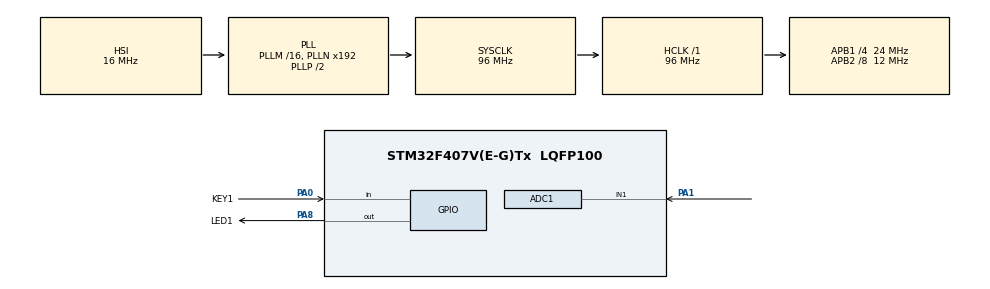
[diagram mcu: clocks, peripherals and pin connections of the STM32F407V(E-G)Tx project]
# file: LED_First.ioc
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ADC1.Channel-1\#ChannelRegularConversion=ADC_CHANNEL_1
ADC1.ContinuousConvMode=ENABLE
ADC1.NbrOfConversionFlag=1
ADC1.Rank-1\#ChannelRegularConversion=1
ADC1.SamplingTime-1\#ChannelRegularConversion=ADC_SAMPLETIME_3CYCLES
ADC1.master=1
FREERTOS.Tasks01=LED_Task,24,128,LED_Entry,As weak,NULL,Static,LED_TaskBuffer,LED_TaskControlBlock
Mcu.Family=STM32F4
Mcu.Name=STM32F407V(E-G)Tx
Mcu.Package=LQFP100
NVIC.PriorityGroup=NVIC_PRIORITYGROUP_4
NVIC.TIM6_DAC_IRQn=true\:15\:0\:false\:false\:true\:false\:false\:true\:true
NVIC.TimeBase=TIM6_DAC_IRQn
NVIC.TimeBaseIP=TIM6
PA0-WKUP.GPIO_Label=KEY1
PA0-WKUP.GPIO_Mode=GPIO_MODE_INPUT
PA0-WKUP.GPIO_PuPd=GPIO_PULLUP
PA0-WKUP.Signal=GPIO_Input
PA1.Signal=ADCx_IN1
PA13.Mode=Serial_Wire
PA13.Signal=SYS_JTMS-SWDIO
PA14.Mode=Serial_Wire
PA14.Signal=SYS_JTCK-SWCLK
PA8.GPIO_Label=LED1
PA8.GPIO_PuPd=GPIO_PULLUP
PA8.Signal=GPIO_Output
PH0-OSC_IN.Mode=HSE-External-Oscillator
PH0-OSC_IN.Signal=RCC_OSC_IN
PH1-OSC_OUT.Mode=HSE-External-Oscillator
PH1-OSC_OUT.Signal=RCC_OSC_OUT
ProjectManager.HeapSize=0x200
ProjectManager.StackSize=0x400
ProjectManager.TargetToolchain=MDK-ARM V5.32
RCC.AHBFreq_Value=96000000
RCC.APB1CLKDivider=RCC_HCLK_DIV4
RCC.APB1Freq_Value=24000000
RCC.APB1TimFreq_Value=48000000
RCC.APB2CLKDivider=RCC_HCLK_DIV8
RCC.APB2Freq_Value=12000000
RCC.APB2TimFreq_Value=24000000
RCC.CortexFreq_Value=96000000
RCC.HCLKFreq_Value=96000000
RCC.HSE_VALUE=25000000
RCC.HSI_VALUE=16000000
RCC.LSE_VALUE=32768
RCC.SYSCLKFreq_VALUE=96000000
RCC.SYSCLKSource=RCC_SYSCLKSOURCE_PLLCLK
RCC.VCOOutputFreq_Value=192000000
SH.ADCx_IN1.0=ADC1_IN1,IN1
VP_FREERTOS_VS_CMSIS_V2.Mode=CMSIS_V2
VP_SYS_VS_tim6.Mode=TIM6
board=custom

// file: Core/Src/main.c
/* USER CODE BEGIN Header */
/**
  ******************************************************************************
  * @file           : main.c
  * @brief          : Main program body
  ******************************************************************************
  * @attention
  *
  * Copyright (c) 2023 STMicroelectronics.
  * All rights reserved.
  *
  * This software is licensed under terms that can be found in the LICENSE file
  * in the root directory of this software component.
  * If no LICENSE file comes with this software, it is provided AS-IS.
  *
  ******************************************************************************
  */
/* USER CODE END Header */
#include "main.h"
#include "cmsis_os.h"
#include "adc.h"
#include "gpio.h"

/* USER CODE BEGIN Includes */
// #include "SEGGER_RRT.h"

/* USER CODE END Includes */

void SystemClock_Config(void);
void MX_FREERTOS_Init(void);

int main(void)
{

  /* MCU Configuration--------------------------------------------------------*/

  /* Reset of all peripherals, Initializes the Flash interface and the Systick. */
  HAL_Init();

  /* Configure the system clock */
  SystemClock_Config();

  /* Initialize all configured peripherals */
  MX_GPIO_Init();
  MX_ADC1_Init();

  /* Init scheduler */
  osKernelInitialize();  /* Call init function for freertos objects (in freertos.c) */
  MX_FREERTOS_Init();

  /* Start scheduler */
  osKernelStart();

  /* We should never get here as control is now taken by the scheduler */
  /* Infinite loop */
  while (1)
  {

  }
}

void SystemClock_Config(void)
{
  RCC_OscInitTypeDef RCC_OscInitStruct = {0};
  RCC_ClkInitTypeDef RCC_ClkInitStruct = {0};

  /** Configure the main internal regulator output voltage
  */
  __HAL_RCC_PWR_CLK_ENABLE();
  __HAL_PWR_VOLTAGESCALING_CONFIG(PWR_REGULATOR_VOLTAGE_SCALE1);

  /** Initializes the RCC Oscillators according to the specified parameters
  * in the RCC_OscInitTypeDef structure.
  */
  RCC_OscInitStruct.OscillatorType = RCC_OSCILLATORTYPE_HSI;
  RCC_OscInitStruct.HSIState = RCC_HSI_ON;
  RCC_OscInitStruct.HSICalibrationValue = RCC_HSICALIBRATION_DEFAULT;
  RCC_OscInitStruct.PLL.PLLState = RCC_PLL_ON;
  RCC_OscInitStruct.PLL.PLLSource = RCC_PLLSOURCE_HSI;
  RCC_OscInitStruct.PLL.PLLM = 16;
  RCC_OscInitStruct.PLL.PLLN = 192;
  RCC_OscInitStruct.PLL.PLLP = RCC_PLLP_DIV2;
  RCC_OscInitStruct.PLL.PLLQ = 4;
  if (HAL_RCC_OscConfig(&RCC_OscInitStruct) != HAL_OK)
  {
    Error_Handler();
  }

  /** Initializes the CPU, AHB and APB buses clocks
  */
  RCC_ClkInitStruct.ClockType = RCC_CLOCKTYPE_HCLK|RCC_CLOCKTYPE_SYSCLK
                              |RCC_CLOCKTYPE_PCLK1|RCC_CLOCKTYPE_PCLK2;
  RCC_ClkInitStruct.SYSCLKSource = RCC_SYSCLKSOURCE_PLLCLK;
  RCC_ClkInitStruct.AHBCLKDivider = RCC_SYSCLK_DIV1;
  RCC_ClkInitStruct.APB1CLKDivider = RCC_HCLK_DIV4;
  RCC_ClkInitStruct.APB2CLKDivider = RCC_HCLK_DIV8;

  if (HAL_RCC_ClockConfig(&RCC_ClkInitStruct, FLASH_LATENCY_3) != HAL_OK)
  {
    Error_Handler();
  }
}

void HAL_TIM_PeriodElapsedCallback(TIM_HandleTypeDef *htim)
{
  if (htim->Instance == TIM6) {
    HAL_IncTick();
  }
}

void Error_Handler(void)
{
  __disable_irq();
  while (1)
  {
  }
}

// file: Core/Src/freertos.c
/* USER CODE BEGIN Header */
/**
  ******************************************************************************
  * File Name          : freertos.c
  * Description        : Code for freertos applications
  ******************************************************************************
  * @attention
  *
  * Copyright (c) 2023 STMicroelectronics.
  * All rights reserved.
  *
  * This software is licensed under terms that can be found in the LICENSE file
  * in the root directory of this software component.
  * If no LICENSE file comes with this software, it is provided AS-IS.
  *
  ******************************************************************************
  */
/* USER CODE END Header */

#include "FreeRTOS.h"
#include "task.h"
#include "main.h"
#include "cmsis_os.h"

typedef StaticTask_t osStaticThreadDef_t;

/* Definitions for LED_Task */
osThreadId_t LED_TaskHandle;
uint32_t LED_TaskBuffer[ 128 ];
osStaticThreadDef_t LED_TaskControlBlock;
const osThreadAttr_t LED_Task_attributes = {
  .name = "LED_Task",
  .cb_mem = &LED_TaskControlBlock,
  .cb_size = sizeof(LED_TaskControlBlock),
  .stack_mem = &LED_TaskBuffer[0],
  .stack_size = sizeof(LED_TaskBuffer),
  .priority = (osPriority_t) osPriorityNormal,
};

void LED_Entry(void *argument);

void MX_FREERTOS_Init(void); /* (MISRA C 2004 rule 8.1) */

void MX_FREERTOS_Init(void) {

  /* Create the thread(s) */
  /* creation of LED_Task */
  LED_TaskHandle = osThreadNew(LED_Entry, NULL, &LED_Task_attributes);

}

__weak void LED_Entry(void *argument)
{
  for(;;)
  {
    osDelay(1);
  }
}
